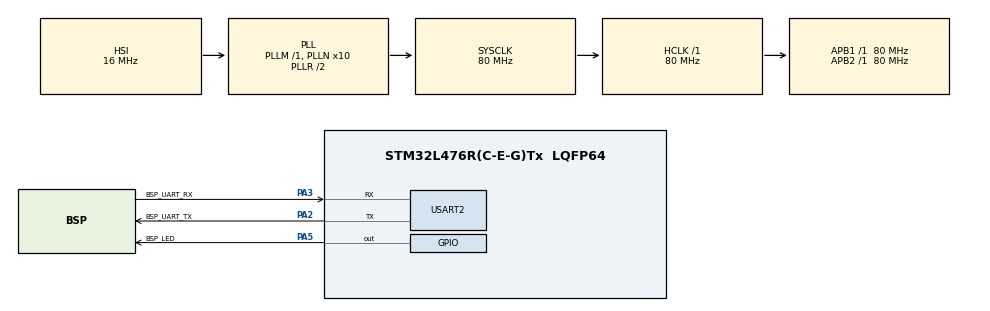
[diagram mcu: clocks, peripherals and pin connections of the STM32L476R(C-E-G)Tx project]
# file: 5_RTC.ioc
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Mcu.Family=STM32L4
Mcu.Name=STM32L476R(C-E-G)Tx
Mcu.Package=LQFP64
NVIC.PriorityGroup=NVIC_PRIORITYGROUP_4
NVIC.USART2_IRQn=true\:0\:0\:false\:false\:true\:true\:true\:true
PA13\ (JTMS-SWDIO).Mode=Serial_Wire
PA13\ (JTMS-SWDIO).Signal=SYS_JTMS-SWDIO
PA14\ (JTCK-SWCLK).Mode=Serial_Wire
PA14\ (JTCK-SWCLK).Signal=SYS_JTCK-SWCLK
PA2.GPIO_Label=BSP_UART_TX
PA2.Mode=Asynchronous
PA2.Signal=USART2_TX
PA3.GPIO_Label=BSP_UART_RX
PA3.Mode=Asynchronous
PA3.Signal=USART2_RX
PA5.GPIO_Label=BSP_LED
PA5.Signal=GPIO_Output
PC14-OSC32_IN\ (PC14).Mode=LSE-External-Oscillator
PC14-OSC32_IN\ (PC14).Signal=RCC_OSC32_IN
PC15-OSC32_OUT\ (PC15).Mode=LSE-External-Oscillator
PC15-OSC32_OUT\ (PC15).Signal=RCC_OSC32_OUT
PH0-OSC_IN\ (PH0).Mode=HSE-External-Oscillator
PH0-OSC_IN\ (PH0).Signal=RCC_OSC_IN
PH1-OSC_OUT\ (PH1).Mode=HSE-External-Oscillator
PH1-OSC_OUT\ (PH1).Signal=RCC_OSC_OUT
ProjectManager.HeapSize=0x200
ProjectManager.StackSize=0x400
ProjectManager.TargetToolchain=STM32CubeIDE
RCC.ADCFreq_Value=64000000
RCC.AHBFreq_Value=80000000
RCC.APB1Freq_Value=80000000
RCC.APB1TimFreq_Value=80000000
RCC.APB2Freq_Value=80000000
RCC.APB2TimFreq_Value=80000000
RCC.CortexFreq_Value=80000000
RCC.HCLKFreq_Value=80000000
RCC.HSE_VALUE=8000000
RCC.HSI_VALUE=16000000
RCC.MSI_VALUE=4000000
RCC.PLLN=10
RCC.PLLSourceVirtual=RCC_PLLSOURCE_HSI
RCC.PREFETCH_ENABLE=1
RCC.RTCClockSelection=RCC_RTCCLKSOURCE_LSE
RCC.SYSCLKFreq_VALUE=80000000
RCC.SYSCLKSource=RCC_SYSCLKSOURCE_PLLCLK
RCC.USBFreq_Value=64000000
RCC.VCOOutputFreq_Value=160000000
RTC.Date=9
RTC.Hours=2
RTC.Minutes=5
RTC.Month=RTC_MONTH_APRIL
RTC.WeekDay=RTC_WEEKDAY_TUESDAY
RTC.Year=24
USART2.VirtualMode-Asynchronous=VM_ASYNC
VP_RTC_VS_RTC_Activate.Mode=RTC_Enabled
VP_RTC_VS_RTC_Calendar.Mode=RTC_Calendar
board=NUCLEO-L476RG

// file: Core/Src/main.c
/* USER CODE BEGIN Header */
/**
  ******************************************************************************
  * @file           : main.c
  * @brief          : Main program body
  ******************************************************************************
  * @attention
  *
  * Copyright (c) 2024 STMicroelectronics.
  * All rights reserved.
  *
  * This software is licensed under terms that can be found in the LICENSE file
  * in the root directory of this software component.
  * If no LICENSE file comes with this software, it is provided AS-IS.
  *
  ******************************************************************************
  */
/* USER CODE END Header */
#include "main.h"

/* USER CODE BEGIN Includes */

#include <stdio.h>
#include <string.h>

/* USER CODE END Includes */

RTC_HandleTypeDef hrtc;

UART_HandleTypeDef huart2;

/* USER CODE BEGIN PV */

RTC_TimeTypeDef sTime;

RTC_DateTypeDef sDate;

char date[30];

char time[30];
/* USER CODE END PV */

void SystemClock_Config(void);
static void MX_GPIO_Init(void);
static void MX_USART2_UART_Init(void);
static void MX_RTC_Init(void);

int main(void)
{

  /* MCU Configuration--------------------------------------------------------*/

  /* Reset of all peripherals, Initializes the Flash interface and the Systick. */
  HAL_Init();

  /* Configure the system clock */
  SystemClock_Config();

  /* Initialize all configured peripherals */
  MX_GPIO_Init();
  MX_USART2_UART_Init();
  MX_RTC_Init();

  /* Infinite loop */
  while (1)
  {

    /* USER CODE BEGIN 3 */

//	  printf("Hello, Dishant!!\r\n");
//	  HAL_Delay(500);

	  HAL_RTC_GetTime(&hrtc, &sTime, RTC_FORMAT_BIN);
	  HAL_RTC_GetDate(&hrtc, &sDate, RTC_FORMAT_BIN);

	  sprintf(date , "Date : %02d.%02d.%02d \t", sDate.Date, sDate.Month, sDate.Year);
	  sprintf(time , "Time : %02d.%02d.%02d\r\n",sTime.Hours, sTime.Minutes, sTime.Seconds );

	  HAL_UART_Transmit(&huart2, (uint8_t *)date, sizeof(date), 300);
	  HAL_UART_Transmit(&huart2, (uint8_t *)time, sizeof(time), 300);
	  HAL_Delay(1000);
  }
  /* USER CODE END 3 */
}

void SystemClock_Config(void)
{
  RCC_OscInitTypeDef RCC_OscInitStruct = {0};
  RCC_ClkInitTypeDef RCC_ClkInitStruct = {0};

  /** Configure the main internal regulator output voltage
  */
  if (HAL_PWREx_ControlVoltageScaling(PWR_REGULATOR_VOLTAGE_SCALE1) != HAL_OK)
  {
    Error_Handler();
  }

  /** Configure LSE Drive Capability
  */
  HAL_PWR_EnableBkUpAccess();
  __HAL_RCC_LSEDRIVE_CONFIG(RCC_LSEDRIVE_LOW);

  /** Initializes the RCC Oscillators according to the specified parameters
  * in the RCC_OscInitTypeDef structure.
  */
  RCC_OscInitStruct.OscillatorType = RCC_OSCILLATORTYPE_HSI|RCC_OSCILLATORTYPE_LSE;
  RCC_OscInitStruct.LSEState = RCC_LSE_ON;
  RCC_OscInitStruct.HSIState = RCC_HSI_ON;
  RCC_OscInitStruct.HSICalibrationValue = RCC_HSICALIBRATION_DEFAULT;
  RCC_OscInitStruct.PLL.PLLState = RCC_PLL_ON;
  RCC_OscInitStruct.PLL.PLLSource = RCC_PLLSOURCE_HSI;
  RCC_OscInitStruct.PLL.PLLM = 1;
  RCC_OscInitStruct.PLL.PLLN = 10;
  RCC_OscInitStruct.PLL.PLLP = RCC_PLLP_DIV7;
  RCC_OscInitStruct.PLL.PLLQ = RCC_PLLQ_DIV2;
  RCC_OscInitStruct.PLL.PLLR = RCC_PLLR_DIV2;
  if (HAL_RCC_OscConfig(&RCC_OscInitStruct) != HAL_OK)
  {
    Error_Handler();
  }

  /** Initializes the CPU, AHB and APB buses clocks
  */
  RCC_ClkInitStruct.ClockType = RCC_CLOCKTYPE_HCLK|RCC_CLOCKTYPE_SYSCLK
                              |RCC_CLOCKTYPE_PCLK1|RCC_CLOCKTYPE_PCLK2;
  RCC_ClkInitStruct.SYSCLKSource = RCC_SYSCLKSOURCE_PLLCLK;
  RCC_ClkInitStruct.AHBCLKDivider = RCC_SYSCLK_DIV1;
  RCC_ClkInitStruct.APB1CLKDivider = RCC_HCLK_DIV1;
  RCC_ClkInitStruct.APB2CLKDivider = RCC_HCLK_DIV1;

  if (HAL_RCC_ClockConfig(&RCC_ClkInitStruct, FLASH_LATENCY_4) != HAL_OK)
  {
    Error_Handler();
  }
}

static void MX_RTC_Init(void)
{

  RTC_TimeTypeDef sTime = {0};
  RTC_DateTypeDef sDate = {0};

  /** Initialize RTC Only
  */
  hrtc.Instance = RTC;
  hrtc.Init.HourFormat = RTC_HOURFORMAT_24;
  hrtc.Init.AsynchPrediv = 127;
  hrtc.Init.SynchPrediv = 255;
  hrtc.Init.OutPut = RTC_OUTPUT_DISABLE;
  hrtc.Init.OutPutRemap = RTC_OUTPUT_REMAP_NONE;
  hrtc.Init.OutPutPolarity = RTC_OUTPUT_POLARITY_HIGH;
  hrtc.Init.OutPutType = RTC_OUTPUT_TYPE_OPENDRAIN;
  if (HAL_RTC_Init(&hrtc) != HAL_OK)
  {
    Error_Handler();
  }

  /** Initialize RTC and set the Time and Date
  */
  sTime.Hours = 0x2;
  sTime.Minutes = 0x5;
  sTime.Seconds = 0x0;
  sTime.DayLightSaving = RTC_DAYLIGHTSAVING_NONE;
  sTime.StoreOperation = RTC_STOREOPERATION_RESET;
  if (HAL_RTC_SetTime(&hrtc, &sTime, RTC_FORMAT_BCD) != HAL_OK)
  {
    Error_Handler();
  }
  sDate.WeekDay = RTC_WEEKDAY_TUESDAY;
  sDate.Month = RTC_MONTH_APRIL;
  sDate.Date = 0x9;
  sDate.Year = 0x24;

  if (HAL_RTC_SetDate(&hrtc, &sDate, RTC_FORMAT_BCD) != HAL_OK)
  {
    Error_Handler();
  }

}

static void MX_USART2_UART_Init(void)
{

  huart2.Instance = USART2;
  huart2.Init.BaudRate = 115200;
  huart2.Init.WordLength = UART_WORDLENGTH_8B;
  huart2.Init.StopBits = UART_STOPBITS_1;
  huart2.Init.Parity = UART_PARITY_NONE;
  huart2.Init.Mode = UART_MODE_TX_RX;
  huart2.Init.HwFlowCtl = UART_HWCONTROL_NONE;
  huart2.Init.OverSampling = UART_OVERSAMPLING_16;
  huart2.Init.OneBitSampling = UART_ONE_BIT_SAMPLE_DISABLE;
  huart2.AdvancedInit.AdvFeatureInit = UART_ADVFEATURE_NO_INIT;
  if (HAL_UART_Init(&huart2) != HAL_OK)
  {
    Error_Handler();
  }

}

static void MX_GPIO_Init(void)
{
  GPIO_InitTypeDef GPIO_InitStruct = {0};

  /* GPIO Ports Clock Enable */
  __HAL_RCC_GPIOC_CLK_ENABLE();
  __HAL_RCC_GPIOH_CLK_ENABLE();
  __HAL_RCC_GPIOA_CLK_ENABLE();

  /*Configure GPIO pin Output Level */
  HAL_GPIO_WritePin(BSP_LED_GPIO_Port, BSP_LED_Pin, GPIO_PIN_RESET);

  /*Configure GPIO pin : BSP_LED_Pin */
  GPIO_InitStruct.Pin = BSP_LED_Pin;
  GPIO_InitStruct.Mode = GPIO_MODE_OUTPUT_PP;
  GPIO_InitStruct.Pull = GPIO_NOPULL;
  GPIO_InitStruct.Speed = GPIO_SPEED_FREQ_LOW;
  HAL_GPIO_Init(BSP_LED_GPIO_Port, &GPIO_InitStruct);

}

void Error_Handler(void)
{
  __disable_irq();
  while (1)
  {
  }
}
